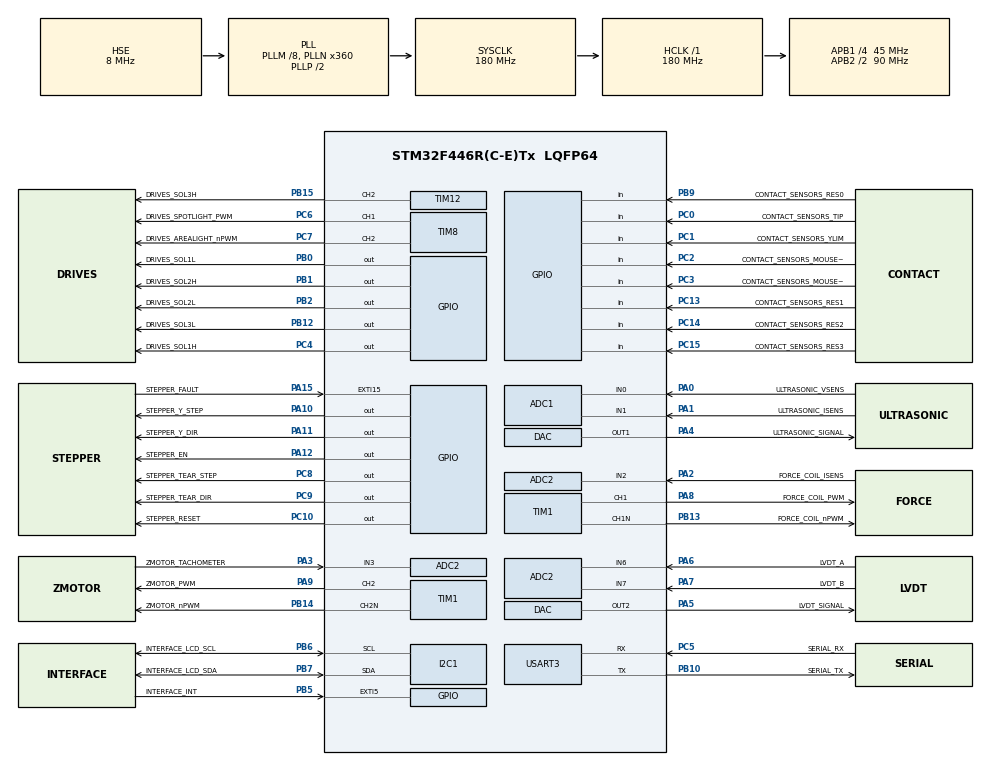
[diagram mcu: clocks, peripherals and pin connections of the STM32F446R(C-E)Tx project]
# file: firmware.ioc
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ADC1.Channel-1\#ChannelRegularConversion=ADC_CHANNEL_0
ADC1.Channel-2\#ChannelRegularConversion=ADC_CHANNEL_1
ADC1.ClockPrescaler=ADC_CLOCK_SYNC_PCLK_DIV4
ADC1.DMAContinuousRequests=ENABLE
ADC1.ExternalTrigConv=ADC_EXTERNALTRIGCONV_T2_TRGO
ADC1.NbrOfConversion=2
ADC1.NbrOfConversionFlag=1
ADC1.Rank-1\#ChannelRegularConversion=1
ADC1.Rank-2\#ChannelRegularConversion=2
ADC1.SamplingTime-1\#ChannelRegularConversion=ADC_SAMPLETIME_3CYCLES
ADC1.SamplingTime-2\#ChannelRegularConversion=ADC_SAMPLETIME_3CYCLES
ADC1.master=1
ADC2.Channel-0\#ChannelRegularConversion=ADC_CHANNEL_2
ADC2.Channel-1\#ChannelRegularConversion=ADC_CHANNEL_3
ADC2.Channel-2\#ChannelRegularConversion=ADC_CHANNEL_6
ADC2.Channel-3\#ChannelRegularConversion=ADC_CHANNEL_7
ADC2.DMAContinuousRequests=ENABLE
ADC2.ExternalTrigConv=ADC_EXTERNALTRIGCONV_T3_TRGO
ADC2.NbrOfConversion=4
ADC2.NbrOfConversionFlag=1
ADC2.Rank-0\#ChannelRegularConversion=1
ADC2.Rank-1\#ChannelRegularConversion=2
ADC2.Rank-2\#ChannelRegularConversion=3
ADC2.Rank-3\#ChannelRegularConversion=4
ADC2.SamplingTime-0\#ChannelRegularConversion=ADC_SAMPLETIME_15CYCLES
ADC2.SamplingTime-1\#ChannelRegularConversion=ADC_SAMPLETIME_15CYCLES
ADC2.SamplingTime-2\#ChannelRegularConversion=ADC_SAMPLETIME_15CYCLES
ADC2.SamplingTime-3\#ChannelRegularConversion=ADC_SAMPLETIME_15CYCLES
DAC.DAC_OutputBuffer=DAC_OUTPUTBUFFER_DISABLE
DAC.DAC_OutputBuffer2=DAC_OUTPUTBUFFER_DISABLE
DAC.DAC_Trigger=DAC_TRIGGER_T4_TRGO
DAC.DAC_Trigger2=DAC_TRIGGER_T5_TRGO
Dma.ADC1.2.Direction=DMA_PERIPH_TO_MEMORY
Dma.ADC1.2.FIFOMode=DMA_FIFOMODE_DISABLE
Dma.ADC1.2.Instance=DMA2_Stream0
Dma.ADC1.2.MemDataAlignment=DMA_MDATAALIGN_HALFWORD
Dma.ADC1.2.MemInc=DMA_MINC_ENABLE
Dma.ADC1.2.Mode=DMA_CIRCULAR
Dma.ADC1.2.PeriphDataAlignment=DMA_PDATAALIGN_HALFWORD
Dma.ADC1.2.PeriphInc=DMA_PINC_DISABLE
Dma.ADC1.2.Priority=DMA_PRIORITY_VERY_HIGH
Dma.ADC2.3.Direction=DMA_PERIPH_TO_MEMORY
Dma.ADC2.3.FIFOMode=DMA_FIFOMODE_DISABLE
Dma.ADC2.3.Instance=DMA2_Stream3
Dma.ADC2.3.MemDataAlignment=DMA_MDATAALIGN_HALFWORD
Dma.ADC2.3.MemInc=DMA_MINC_ENABLE
Dma.ADC2.3.Mode=DMA_CIRCULAR
Dma.ADC2.3.PeriphDataAlignment=DMA_PDATAALIGN_HALFWORD
Dma.ADC2.3.PeriphInc=DMA_PINC_DISABLE
Dma.ADC2.3.Priority=DMA_PRIORITY_HIGH
Dma.DAC1.0.Direction=DMA_MEMORY_TO_PERIPH
Dma.DAC1.0.FIFOMode=DMA_FIFOMODE_DISABLE
Dma.DAC1.0.Instance=DMA1_Stream5
Dma.DAC1.0.MemDataAlignment=DMA_MDATAALIGN_HALFWORD
Dma.DAC1.0.MemInc=DMA_MINC_ENABLE
Dma.DAC1.0.Mode=DMA_CIRCULAR
Dma.DAC1.0.PeriphDataAlignment=DMA_PDATAALIGN_HALFWORD
Dma.DAC1.0.PeriphInc=DMA_PINC_DISABLE
Dma.DAC1.0.Priority=DMA_PRIORITY_VERY_HIGH
Dma.DAC2.1.Direction=DMA_MEMORY_TO_PERIPH
Dma.DAC2.1.FIFOMode=DMA_FIFOMODE_DISABLE
Dma.DAC2.1.Instance=DMA1_Stream6
Dma.DAC2.1.MemDataAlignment=DMA_MDATAALIGN_HALFWORD
Dma.DAC2.1.MemInc=DMA_MINC_ENABLE
Dma.DAC2.1.Mode=DMA_CIRCULAR
Dma.DAC2.1.PeriphDataAlignment=DMA_PDATAALIGN_HALFWORD
Dma.DAC2.1.PeriphInc=DMA_PINC_DISABLE
Dma.DAC2.1.Priority=DMA_PRIORITY_HIGH
Dma.Request0=DAC1
Dma.Request1=DAC2
Dma.Request2=ADC1
Dma.Request3=ADC2
Dma.Request4=TIM1_CH1
Dma.Request5=TIM1_CH2
Dma.TIM1_CH1.4.Direction=DMA_MEMORY_TO_PERIPH
Dma.TIM1_CH1.4.FIFOMode=DMA_FIFOMODE_DISABLE
Dma.TIM1_CH1.4.Instance=DMA2_Stream1
Dma.TIM1_CH1.4.MemDataAlignment=DMA_MDATAALIGN_HALFWORD
Dma.TIM1_CH1.4.MemInc=DMA_MINC_ENABLE
Dma.TIM1_CH1.4.Mode=DMA_CIRCULAR
Dma.TIM1_CH1.4.PeriphDataAlignment=DMA_PDATAALIGN_HALFWORD
Dma.TIM1_CH1.4.PeriphInc=DMA_PINC_DISABLE
Dma.TIM1_CH1.4.Priority=DMA_PRIORITY_MEDIUM
Dma.TIM1_CH2.5.Direction=DMA_MEMORY_TO_PERIPH
Dma.TIM1_CH2.5.FIFOMode=DMA_FIFOMODE_DISABLE
Dma.TIM1_CH2.5.Instance=DMA2_Stream2
Dma.TIM1_CH2.5.MemDataAlignment=DMA_MDATAALIGN_HALFWORD
Dma.TIM1_CH2.5.MemInc=DMA_MINC_ENABLE
Dma.TIM1_CH2.5.Mode=DMA_CIRCULAR
Dma.TIM1_CH2.5.PeriphDataAlignment=DMA_PDATAALIGN_HALFWORD
Dma.TIM1_CH2.5.PeriphInc=DMA_PINC_DISABLE
Dma.TIM1_CH2.5.Priority=DMA_PRIORITY_MEDIUM
I2C1.I2C_Mode=I2C_Standard
Mcu.Family=STM32F4
Mcu.Name=STM32F446R(C-E)Tx
Mcu.Package=LQFP64
Mcu.UserConstants=TIM5_CLOCK_FREQ,90000000;ADC2_SAMPLING_FREQ,60000;DAC1_SAMPLING_FREQ,360000;ADC1_SAMPLING_FREQ,360000;DAC2_SAMPLING_FREQ,60000;STEPPER_ISR_FREQ,20000;TIM3_CLOCK_FREQ,90000000;TIM3_RELOAD_VALUE,((TIM3_CLOCK_FREQ/ADC2_SAMPLING_FREQ)-1);TIM1_CLOCK_FREQ,180000000;TIM4_RELOAD_VALUE,((TIM4_CLOCK_FREQ/DAC1_SAMPLING_FREQ)-1);TIM5_RELOAD_VALUE,((TIM5_CLOCK_FREQ/DAC2_SAMPLING_FREQ)-1);TIM6_RELOAD_VALUE,((TIM6_CLOCK_FREQ/STEPPER_ISR_FREQ)-1);TIM4_CLOCK_FREQ,90000000;TIM2_RELOAD_VALUE,((TIM2_CLOCK_FREQ/ADC1_SAMPLING_FREQ)-1);TIM6_CLOCK_FREQ,90000000;TIM1_PWM_FREQ,30000;TIM2_CLOCK_FREQ,90000000;TIM1_RELOAD_VALUE,((TIM1_CLOCK_FREQ/TIM1_PWM_FREQ)-1);TIM12_CLOCK_FREQ,90000000;TIM12_PWM_FREQ,20000;TIM12_RELOAD_VALUE,((TIM12_CLOCK_FREQ/TIM12_PWM_FREQ)-1)
NVIC.DMA1_Stream5_IRQn=true\:0\:0\:false\:false\:true\:false\:true\:true
NVIC.DMA1_Stream6_IRQn=true\:0\:0\:false\:false\:true\:false\:true\:true
NVIC.DMA2_Stream0_IRQn=true\:0\:0\:false\:false\:true\:false\:true\:true
NVIC.DMA2_Stream1_IRQn=true\:0\:0\:false\:false\:true\:false\:true\:true
NVIC.DMA2_Stream2_IRQn=true\:0\:0\:false\:false\:true\:false\:true\:true
NVIC.DMA2_Stream3_IRQn=true\:0\:0\:false\:false\:true\:false\:true\:true
NVIC.I2C1_EV_IRQn=true\:0\:0\:false\:false\:true\:true\:true\:true
NVIC.PriorityGroup=NVIC_PRIORITYGROUP_4
NVIC.TIM6_DAC_IRQn=true\:0\:0\:false\:false\:true\:true\:true\:true
PA0-WKUP.GPIO_Label=ULTRASONIC_VSENS
PA0-WKUP.Signal=ADCx_IN0
PA1.GPIO_Label=ULTRASONIC_ISENS
PA1.Signal=ADCx_IN1
PA10.GPIO_Label=STEPPER_Y_STEP
PA10.Signal=GPIO_Output
PA11.GPIO_Label=STEPPER_Y_DIR
PA11.Signal=GPIO_Output
PA12.GPIO_Label=STEPPER_EN
PA12.Signal=GPIO_Output
PA13.Mode=Serial_Wire
PA13.Signal=SYS_JTMS-SWDIO
PA14.Mode=Serial_Wire
PA14.Signal=SYS_JTCK-SWCLK
PA15.GPIO_Label=STEPPER_FAULT
PA15.Signal=GPXTI15
PA2.GPIO_Label=FORCE_COIL_ISENS
PA2.Signal=ADCx_IN2
PA3.GPIO_Label=ZMOTOR_TACHOMETER
PA3.Signal=ADCx_IN3
PA4.GPIO_Label=ULTRASONIC_SIGNAL
PA4.Signal=COMP_DAC1_group
PA5.GPIO_Label=LVDT_SIGNAL
PA5.Signal=COMP_DAC2_group
PA6.GPIO_Label=LVDT_A
PA6.Signal=ADCx_IN6
PA7.GPIO_Label=LVDT_B
PA7.Signal=ADCx_IN7
PA8.GPIO_Label=FORCE_COIL_PWM
PA8.Signal=S_TIM1_CH1
PA9.GPIO_Label=ZMOTOR_PWM
PA9.Signal=S_TIM1_CH2
PB0.GPIO_Label=DRIVES_SOL1L
PB0.PinState=GPIO_PIN_SET
PB0.Signal=GPIO_Output
PB1.GPIO_Label=DRIVES_SOL2H
PB1.Signal=GPIO_Output
PB10.GPIO_Label=SERIAL_TX
PB10.Mode=Asynchronous
PB10.Signal=USART3_TX
PB12.GPIO_Label=DRIVES_SOL3L
PB12.PinState=GPIO_PIN_SET
PB12.Signal=GPIO_Output
PB13.GPIO_Label=FORCE_COIL_nPWM
PB13.Mode=PWM Generation1 CH1 CH1N
PB13.Signal=TIM1_CH1N
PB14.GPIO_Label=ZMOTOR_nPWM
PB14.Mode=PWM Generation2 CH2 CH2N
PB14.Signal=TIM1_CH2N
PB15.GPIO_Label=DRIVES_SOL3H
PB15.Signal=S_TIM12_CH2
PB2.GPIO_Label=DRIVES_SOL2L
PB2.PinState=GPIO_PIN_SET
PB2.Signal=GPIO_Output
PB5.GPIO_Label=INTERFACE_INT
PB5.Signal=GPXTI5
PB6.GPIO_Label=INTERFACE_LCD_SCL
PB6.Mode=I2C
PB6.Signal=I2C1_SCL
PB7.GPIO_Label=INTERFACE_LCD_SDA
PB7.Mode=I2C
PB7.Signal=I2C1_SDA
PB9.GPIO_Label=CONTACT_SENSORS_RES0
PB9.Signal=GPIO_Input
PC0.GPIO_Label=CONTACT_SENSORS_TIP
PC0.Signal=GPIO_Input
PC1.GPIO_Label=CONTACT_SENSORS_YLIM
PC1.Signal=GPIO_Input
PC10.GPIO_Label=STEPPER_RESET
PC10.Signal=GPIO_Output
PC13.GPIO_Label=CONTACT_SENSORS_RES1
PC13.Signal=GPIO_Input
PC14-OSC32_IN.GPIO_Label=CONTACT_SENSORS_RES2
PC14-OSC32_IN.Signal=GPIO_Input
PC15-OSC32_OUT.GPIO_Label=CONTACT_SENSORS_RES3
PC15-OSC32_OUT.Signal=GPIO_Input
PC2.GPIO_Label=CONTACT_SENSORS_MOUSE_LEFT
PC2.Signal=GPIO_Input
PC3.GPIO_Label=CONTACT_SENSORS_MOUSE_RIGHT
PC3.Signal=GPIO_Input
PC4.GPIO_Label=DRIVES_SOL1H
PC4.Signal=GPIO_Output
PC5.GPIO_Label=SERIAL_RX
PC5.Mode=Asynchronous
PC5.Signal=USART3_RX
PC6.GPIO_Label=DRIVES_SPOTLIGHT_PWM
PC6.Signal=S_TIM8_CH1
PC7.GPIO_Label=DRIVES_AREALIGHT_nPWM
PC7.Signal=S_TIM8_CH2
PC8.GPIO_Label=STEPPER_TEAR_STEP
PC8.Signal=GPIO_Output
PC9.GPIO_Label=STEPPER_TEAR_DIR
PC9.Signal=GPIO_Output
PH0-OSC_IN.Mode=HSE-External-Oscillator
PH0-OSC_IN.Signal=RCC_OSC_IN
PH1-OSC_OUT.Mode=HSE-External-Oscillator
PH1-OSC_OUT.Signal=RCC_OSC_OUT
ProjectManager.HeapSize=0x200
ProjectManager.StackSize=0x400
ProjectManager.TargetToolchain=Makefile
RCC.AHBFreq_Value=180000000
RCC.APB1CLKDivider=RCC_HCLK_DIV4
RCC.APB1Freq_Value=45000000
RCC.APB1TimFreq_Value=90000000
RCC.APB2CLKDivider=RCC_HCLK_DIV2
RCC.APB2Freq_Value=90000000
RCC.APB2TimFreq_Value=180000000
RCC.CortexFreq_Value=180000000
RCC.HCLKFreq_Value=180000000
RCC.HSE_VALUE=8000000
RCC.PLLM=8
RCC.PLLN=360
RCC.PLLSourceVirtual=RCC_PLLSOURCE_HSE
RCC.SYSCLKFreq_VALUE=180000000
RCC.SYSCLKSource=RCC_SYSCLKSOURCE_PLLCLK
RCC.USBFreq_Value=180000000
RCC.VCOOutputFreq_Value=360000000
SH.ADCx_IN0.0=ADC1_IN0,IN0
SH.ADCx_IN1.0=ADC1_IN1,IN1
SH.ADCx_IN2.0=ADC2_IN2,IN2
SH.ADCx_IN3.0=ADC2_IN3,IN3
SH.ADCx_IN6.0=ADC2_IN6,IN6
SH.ADCx_IN7.0=ADC2_IN7,IN7
SH.COMP_DAC1_group.0=DAC_OUT1,DAC_OUT1
SH.COMP_DAC2_group.0=DAC_OUT2,DAC_OUT2
SH.S_TIM12_CH2.0=TIM12_CH2,PWM Generation2 CH2
SH.S_TIM1_CH1.0=TIM1_CH1,PWM Generation1 CH1 CH1N
SH.S_TIM1_CH2.0=TIM1_CH2,PWM Generation2 CH2 CH2N
SH.S_TIM8_CH1.0=TIM8_CH1,PWM Generation1 CH1
SH.S_TIM8_CH2.0=TIM8_CH2,PWM Generation2 CH2
TIM1.Channel-PWM\ Generation1\ CH1\ CH1N=TIM_CHANNEL_1
TIM1.Channel-PWM\ Generation2\ CH2\ CH2N=TIM_CHANNEL_2
TIM1.DeadTime=90
TIM1.Period=TIM1_RELOAD_VALUE
TIM12.Channel-PWM\ Generation2\ CH2=TIM_CHANNEL_2
TIM12.Period=TIM12_RELOAD_VALUE
TIM2.Period=TIM2_RELOAD_VALUE
TIM2.TIM_MasterOutputTrigger=TIM_TRGO_UPDATE
TIM3.Period=TIM3_RELOAD_VALUE
TIM3.TIM_MasterOutputTrigger=TIM_TRGO_UPDATE
TIM4.Period=TIM4_RELOAD_VALUE
TIM4.TIM_MasterOutputTrigger=TIM_TRGO_UPDATE
TIM5.Period=TIM5_RELOAD_VALUE
TIM5.TIM_MasterOutputTrigger=TIM_TRGO_UPDATE
TIM6.Period=TIM6_RELOAD_VALUE
TIM8.Channel-PWM\ Generation1\ CH1=TIM_CHANNEL_1
TIM8.Channel-PWM\ Generation2\ CH2=TIM_CHANNEL_2
USART3.VirtualMode=VM_ASYNC
VP_TIM12_VS_ClockSourceINT.Mode=Internal
VP_TIM1_VS_ClockSourceINT.Mode=Internal
VP_TIM2_VS_ClockSourceINT.Mode=Internal
VP_TIM3_VS_ClockSourceINT.Mode=Internal
VP_TIM4_VS_ClockSourceINT.Mode=Internal
VP_TIM5_VS_ClockSourceINT.Mode=Internal
VP_TIM6_VS_ClockSourceINT.Mode=Enable_Timer
VP_TIM8_VS_ClockSourceINT.Mode=Internal
board=custom

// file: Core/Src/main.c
/* USER CODE BEGIN Header */
/**
  ******************************************************************************
  * @file           : main.c
  * @brief          : Main program body
  ******************************************************************************
  * @attention
  *
  * Copyright (c) 2024 STMicroelectronics.
  * All rights reserved.
  *
  * This software is licensed under terms that can be found in the LICENSE file
  * in the root directory of this software component.
  * If no LICENSE file comes with this software, it is provided AS-IS.
  *
  ******************************************************************************
  */
/* USER CODE END Header */
#include "main.h"

/* USER CODE BEGIN Includes */
#include "app.h"
#include "configuration.h"
/* USER CODE END Includes */

ADC_HandleTypeDef hadc1;
ADC_HandleTypeDef hadc2;
DMA_HandleTypeDef hdma_adc1;
DMA_HandleTypeDef hdma_adc2;

DAC_HandleTypeDef hdac;
DMA_HandleTypeDef hdma_dac1;
DMA_HandleTypeDef hdma_dac2;

I2C_HandleTypeDef hi2c1;

TIM_HandleTypeDef htim1;
TIM_HandleTypeDef htim2;
TIM_HandleTypeDef htim3;
TIM_HandleTypeDef htim4;
TIM_HandleTypeDef htim5;
TIM_HandleTypeDef htim6;
TIM_HandleTypeDef htim8;
TIM_HandleTypeDef htim12;
DMA_HandleTypeDef hdma_tim1_ch1;
DMA_HandleTypeDef hdma_tim1_ch2;

UART_HandleTypeDef huart3;

void SystemClock_Config(void);
static void MX_GPIO_Init(void);
static void MX_DMA_Init(void);
static void MX_DAC_Init(void);
static void MX_ADC1_Init(void);
static void MX_ADC2_Init(void);
static void MX_I2C1_Init(void);
static void MX_TIM1_Init(void);
static void MX_TIM3_Init(void);
static void MX_TIM8_Init(void);
static void MX_USART3_UART_Init(void);
static void MX_TIM2_Init(void);
static void MX_TIM4_Init(void);
static void MX_TIM5_Init(void);
static void MX_TIM6_Init(void);
static void MX_TIM12_Init(void);

int main(void)
{

  /* MCU Configuration--------------------------------------------------------*/

  /* Reset of all peripherals, Initializes the Flash interface and the Systick. */
  HAL_Init();

  /* Configure the system clock */
  SystemClock_Config();

  /* Initialize all configured peripherals */
  MX_GPIO_Init();
  MX_DMA_Init();
  MX_DAC_Init();
  MX_ADC1_Init();
  MX_ADC2_Init();
  MX_I2C1_Init();
  MX_TIM1_Init();
  MX_TIM3_Init();
  MX_TIM8_Init();
  MX_USART3_UART_Init();
  MX_TIM2_Init();
  MX_TIM4_Init();
  MX_TIM5_Init();
  MX_TIM6_Init();
  MX_TIM12_Init();
  /* USER CODE BEGIN 2 */
  App_Init();
  App_Start();
  /* USER CODE END 2 */

  /* Infinite loop */
  while (1)
  {

    /* USER CODE BEGIN 3 */
    App_Execute();
  }
  /* USER CODE END 3 */
}

void SystemClock_Config(void)
{
  RCC_OscInitTypeDef RCC_OscInitStruct = {0};
  RCC_ClkInitTypeDef RCC_ClkInitStruct = {0};

  /** Configure the main internal regulator output voltage
  */
  __HAL_RCC_PWR_CLK_ENABLE();
  __HAL_PWR_VOLTAGESCALING_CONFIG(PWR_REGULATOR_VOLTAGE_SCALE1);

  /** Initializes the RCC Oscillators according to the specified parameters
  * in the RCC_OscInitTypeDef structure.
  */
  RCC_OscInitStruct.OscillatorType = RCC_OSCILLATORTYPE_HSE;
  RCC_OscInitStruct.HSEState = RCC_HSE_ON;
  RCC_OscInitStruct.PLL.PLLState = RCC_PLL_ON;
  RCC_OscInitStruct.PLL.PLLSource = RCC_PLLSOURCE_HSE;
  RCC_OscInitStruct.PLL.PLLM = 8;
  RCC_OscInitStruct.PLL.PLLN = 360;
  RCC_OscInitStruct.PLL.PLLP = RCC_PLLP_DIV2;
  RCC_OscInitStruct.PLL.PLLQ = 2;
  RCC_OscInitStruct.PLL.PLLR = 2;
  if (HAL_RCC_OscConfig(&RCC_OscInitStruct) != HAL_OK)
  {
    Error_Handler();
  }

  /** Activate the Over-Drive mode
  */
  if (HAL_PWREx_EnableOverDrive() != HAL_OK)
  {
    Error_Handler();
  }

  /** Initializes the CPU, AHB and APB buses clocks
  */
  RCC_ClkInitStruct.ClockType = RCC_CLOCKTYPE_HCLK|RCC_CLOCKTYPE_SYSCLK
                              |RCC_CLOCKTYPE_PCLK1|RCC_CLOCKTYPE_PCLK2;
  RCC_ClkInitStruct.SYSCLKSource = RCC_SYSCLKSOURCE_PLLCLK;
  RCC_ClkInitStruct.AHBCLKDivider = RCC_SYSCLK_DIV1;
  RCC_ClkInitStruct.APB1CLKDivider = RCC_HCLK_DIV4;
  RCC_ClkInitStruct.APB2CLKDivider = RCC_HCLK_DIV2;

  if (HAL_RCC_ClockConfig(&RCC_ClkInitStruct, FLASH_LATENCY_5) != HAL_OK)
  {
    Error_Handler();
  }
}

static void MX_ADC1_Init(void)
{

  ADC_ChannelConfTypeDef sConfig = {0};

  /** Configure the global features of the ADC (Clock, Resolution, Data Alignment and number of conversion)
  */
  hadc1.Instance = ADC1;
  hadc1.Init.ClockPrescaler = ADC_CLOCK_SYNC_PCLK_DIV4;
  hadc1.Init.Resolution = ADC_RESOLUTION_12B;
  hadc1.Init.ScanConvMode = ENABLE;
  hadc1.Init.ContinuousConvMode = DISABLE;
  hadc1.Init.DiscontinuousConvMode = DISABLE;
  hadc1.Init.ExternalTrigConvEdge = ADC_EXTERNALTRIGCONVEDGE_RISING;
  hadc1.Init.ExternalTrigConv = ADC_EXTERNALTRIGCONV_T2_TRGO;
  hadc1.Init.DataAlign = ADC_DATAALIGN_RIGHT;
  hadc1.Init.NbrOfConversion = 2;
  hadc1.Init.DMAContinuousRequests = ENABLE;
  hadc1.Init.EOCSelection = ADC_EOC_SINGLE_CONV;
  if (HAL_ADC_Init(&hadc1) != HAL_OK)
  {
    Error_Handler();
  }

  /** Configure for the selected ADC regular channel its corresponding rank in the sequencer and its sample time.
  */
  sConfig.Channel = ADC_CHANNEL_0;
  sConfig.Rank = 1;
  sConfig.SamplingTime = ADC_SAMPLETIME_3CYCLES;
  if (HAL_ADC_ConfigChannel(&hadc1, &sConfig) != HAL_OK)
  {
    Error_Handler();
  }

  /** Configure for the selected ADC regular channel its corresponding rank in the sequencer and its sample time.
  */
  sConfig.Channel = ADC_CHANNEL_1;
  sConfig.Rank = 2;
  if (HAL_ADC_ConfigChannel(&hadc1, &sConfig) != HAL_OK)
  {
    Error_Handler();
  }

}

static void MX_ADC2_Init(void)
{

  ADC_ChannelConfTypeDef sConfig = {0};

  /** Configure the global features of the ADC (Clock, Resolution, Data Alignment and number of conversion)
  */
  hadc2.Instance = ADC2;
  hadc2.Init.ClockPrescaler = ADC_CLOCK_SYNC_PCLK_DIV4;
  hadc2.Init.Resolution = ADC_RESOLUTION_12B;
  hadc2.Init.ScanConvMode = ENABLE;
  hadc2.Init.ContinuousConvMode = DISABLE;
  hadc2.Init.DiscontinuousConvMode = DISABLE;
  hadc2.Init.ExternalTrigConvEdge = ADC_EXTERNALTRIGCONVEDGE_RISING;
  hadc2.Init.ExternalTrigConv = ADC_EXTERNALTRIGCONV_T3_TRGO;
  hadc2.Init.DataAlign = ADC_DATAALIGN_RIGHT;
  hadc2.Init.NbrOfConversion = 4;
  hadc2.Init.DMAContinuousRequests = ENABLE;
  hadc2.Init.EOCSelection = ADC_EOC_SINGLE_CONV;
  if (HAL_ADC_Init(&hadc2) != HAL_OK)
  {
    Error_Handler();
  }

  /** Configure for the selected ADC regular channel its corresponding rank in the sequencer and its sample time.
  */
  sConfig.Channel = ADC_CHANNEL_2;
  sConfig.Rank = 1;
  sConfig.SamplingTime = ADC_SAMPLETIME_15CYCLES;
  if (HAL_ADC_ConfigChannel(&hadc2, &sConfig) != HAL_OK)
  {
    Error_Handler();
  }

  /** Configure for the selected ADC regular channel its corresponding rank in the sequencer and its sample time.
  */
  sConfig.Channel = ADC_CHANNEL_3;
  sConfig.Rank = 2;
  if (HAL_ADC_ConfigChannel(&hadc2, &sConfig) != HAL_OK)
  {
    Error_Handler();
  }

  /** Configure for the selected ADC regular channel its corresponding rank in the sequencer and its sample time.
  */
  sConfig.Channel = ADC_CHANNEL_6;
  sConfig.Rank = 3;
  if (HAL_ADC_ConfigChannel(&hadc2, &sConfig) != HAL_OK)
  {
    Error_Handler();
  }

  /** Configure for the selected ADC regular channel its corresponding rank in the sequencer and its sample time.
  */
  sConfig.Channel = ADC_CHANNEL_7;
  sConfig.Rank = 4;
  if (HAL_ADC_ConfigChannel(&hadc2, &sConfig) != HAL_OK)
  {
    Error_Handler();
  }

}

static void MX_DAC_Init(void)
{

  DAC_ChannelConfTypeDef sConfig = {0};

  /** DAC Initialization
  */
  hdac.Instance = DAC;
  if (HAL_DAC_Init(&hdac) != HAL_OK)
  {
    Error_Handler();
  }

  /** DAC channel OUT1 config
  */
  sConfig.DAC_Trigger = DAC_TRIGGER_T4_TRGO;
  sConfig.DAC_OutputBuffer = DAC_OUTPUTBUFFER_DISABLE;
  if (HAL_DAC_ConfigChannel(&hdac, &sConfig, DAC_CHANNEL_1) != HAL_OK)
  {
    Error_Handler();
  }

  /** DAC channel OUT2 config
  */
  sConfig.DAC_Trigger = DAC_TRIGGER_T5_TRGO;
  if (HAL_DAC_ConfigChannel(&hdac, &sConfig, DAC_CHANNEL_2) != HAL_OK)
  {
    Error_Handler();
  }

}

static void MX_I2C1_Init(void)
{

  hi2c1.Instance = I2C1;
  hi2c1.Init.ClockSpeed = 100000;
  hi2c1.Init.DutyCycle = I2C_DUTYCYCLE_2;
  hi2c1.Init.OwnAddress1 = 0;
  hi2c1.Init.AddressingMode = I2C_ADDRESSINGMODE_7BIT;
  hi2c1.Init.DualAddressMode = I2C_DUALADDRESS_DISABLE;
  hi2c1.Init.OwnAddress2 = 0;
  hi2c1.Init.GeneralCallMode = I2C_GENERALCALL_DISABLE;
  hi2c1.Init.NoStretchMode = I2C_NOSTRETCH_DISABLE;
  if (HAL_I2C_Init(&hi2c1) != HAL_OK)
  {
    Error_Handler();
  }

}

static void MX_TIM1_Init(void)
{

  TIM_ClockConfigTypeDef sClockSourceConfig = {0};
  TIM_MasterConfigTypeDef sMasterConfig = {0};
  TIM_OC_InitTypeDef sConfigOC = {0};
  TIM_BreakDeadTimeConfigTypeDef sBreakDeadTimeConfig = {0};

  htim1.Instance = TIM1;
  htim1.Init.Prescaler = 0;
  htim1.Init.CounterMode = TIM_COUNTERMODE_UP;
  htim1.Init.Period = TIM1_RELOAD_VALUE;
  htim1.Init.ClockDivision = TIM_CLOCKDIVISION_DIV1;
  htim1.Init.RepetitionCounter = 0;
  htim1.Init.AutoReloadPreload = TIM_AUTORELOAD_PRELOAD_DISABLE;
  if (HAL_TIM_Base_Init(&htim1) != HAL_OK)
  {
    Error_Handler();
  }
  sClockSourceConfig.ClockSource = TIM_CLOCKSOURCE_INTERNAL;
  if (HAL_TIM_ConfigClockSource(&htim1, &sClockSourceConfig) != HAL_OK)
  {
    Error_Handler();
  }
  if (HAL_TIM_PWM_Init(&htim1) != HAL_OK)
  {
    Error_Handler();
  }
  sMasterConfig.MasterOutputTrigger = TIM_TRGO_RESET;
  sMasterConfig.MasterSlaveMode = TIM_MASTERSLAVEMODE_DISABLE;
  if (HAL_TIMEx_MasterConfigSynchronization(&htim1, &sMasterConfig) != HAL_OK)
  {
    Error_Handler();
  }
  sConfigOC.OCMode = TIM_OCMODE_PWM1;
  sConfigOC.Pulse = 0;
  sConfigOC.OCPolarity = TIM_OCPOLARITY_HIGH;
  sConfigOC.OCNPolarity = TIM_OCNPOLARITY_HIGH;
  sConfigOC.OCFastMode = TIM_OCFAST_DISABLE;
  sConfigOC.OCIdleState = TIM_OCIDLESTATE_RESET;
  sConfigOC.OCNIdleState = TIM_OCNIDLESTATE_RESET;
  if (HAL_TIM_PWM_ConfigChannel(&htim1, &sConfigOC, TIM_CHANNEL_1) != HAL_OK)
  {
    Error_Handler();
  }
  if (HAL_TIM_PWM_ConfigChannel(&htim1, &sConfigOC, TIM_CHANNEL_2) != HAL_OK)
  {
    Error_Handler();
  }
  sBreakDeadTimeConfig.OffStateRunMode = TIM_OSSR_DISABLE;
  sBreakDeadTimeConfig.OffStateIDLEMode = TIM_OSSI_DISABLE;
  sBreakDeadTimeConfig.LockLevel = TIM_LOCKLEVEL_OFF;
  sBreakDeadTimeConfig.DeadTime = 90;
  sBreakDeadTimeConfig.BreakState = TIM_BREAK_DISABLE;
  sBreakDeadTimeConfig.BreakPolarity = TIM_BREAKPOLARITY_HIGH;
  sBreakDeadTimeConfig.AutomaticOutput = TIM_AUTOMATICOUTPUT_DISABLE;
  if (HAL_TIMEx_ConfigBreakDeadTime(&htim1, &sBreakDeadTimeConfig) != HAL_OK)
  {
    Error_Handler();
  }
  HAL_TIM_MspPostInit(&htim1);

}

static void MX_TIM2_Init(void)
{

  TIM_ClockConfigTypeDef sClockSourceConfig = {0};
  TIM_MasterConfigTypeDef sMasterConfig = {0};

  htim2.Instance = TIM2;
  htim2.Init.Prescaler = 0;
  htim2.Init.CounterMode = TIM_COUNTERMODE_UP;
  htim2.Init.Period = TIM2_RELOAD_VALUE;
  htim2.Init.ClockDivision = TIM_CLOCKDIVISION_DIV1;
  htim2.Init.AutoReloadPreload = TIM_AUTORELOAD_PRELOAD_DISABLE;
  if (HAL_TIM_Base_Init(&htim2) != HAL_OK)
  {
    Error_Handler();
  }
  sClockSourceConfig.ClockSource = TIM_CLOCKSOURCE_INTERNAL;
  if (HAL_TIM_ConfigClockSource(&htim2, &sClockSourceConfig) != HAL_OK)
  {
    Error_Handler();
  }
  sMasterConfig.MasterOutputTrigger = TIM_TRGO_UPDATE;
  sMasterConfig.MasterSlaveMode = TIM_MASTERSLAVEMODE_DISABLE;
  if (HAL_TIMEx_MasterConfigSynchronization(&htim2, &sMasterConfig) != HAL_OK)
  {
    Error_Handler();
  }

}

static void MX_TIM3_Init(void)
{

  TIM_ClockConfigTypeDef sClockSourceConfig = {0};
  TIM_MasterConfigTypeDef sMasterConfig = {0};

  htim3.Instance = TIM3;
  htim3.Init.Prescaler = 0;
  htim3.Init.CounterMode = TIM_COUNTERMODE_UP;
  htim3.Init.Period = TIM3_RELOAD_VALUE;
  htim3.Init.ClockDivision = TIM_CLOCKDIVISION_DIV1;
  htim3.Init.AutoReloadPreload = TIM_AUTORELOAD_PRELOAD_DISABLE;
  if (HAL_TIM_Base_Init(&htim3) != HAL_OK)
  {
    Error_Handler();
  }
  sClockSourceConfig.ClockSource = TIM_CLOCKSOURCE_INTERNAL;
  if (HAL_TIM_ConfigClockSource(&htim3, &sClockSourceConfig) != HAL_OK)
  {
    Error_Handler();
  }
  sMasterConfig.MasterOutputTrigger = TIM_TRGO_UPDATE;
  sMasterConfig.MasterSlaveMode = TIM_MASTERSLAVEMODE_DISABLE;
  if (HAL_TIMEx_MasterConfigSynchronization(&htim3, &sMasterConfig) != HAL_OK)
  {
    Error_Handler();
  }

}

static void MX_TIM4_Init(void)
{

  TIM_ClockConfigTypeDef sClockSourceConfig = {0};
  TIM_MasterConfigTypeDef sMasterConfig = {0};

  htim4.Instance = TIM4;
  htim4.Init.Prescaler = 0;
  htim4.Init.CounterMode = TIM_COUNTERMODE_UP;
  htim4.Init.Period = TIM4_RELOAD_VALUE;
  htim4.Init.ClockDivision = TIM_CLOCKDIVISION_DIV1;
  htim4.Init.AutoReloadPreload = TIM_AUTORELOAD_PRELOAD_DISABLE;
  if (HAL_TIM_Base_Init(&htim4) != HAL_OK)
  {
    Error_Handler();
  }
  sClockSourceConfig.ClockSource = TIM_CLOCKSOURCE_INTERNAL;
  if (HAL_TIM_ConfigClockSource(&htim4, &sClockSourceConfig) != HAL_OK)
  {
    Error_Handler();
  }
  sMasterConfig.MasterOutputTrigger = TIM_TRGO_UPDATE;
  sMasterConfig.MasterSlaveMode = TIM_MASTERSLAVEMODE_DISABLE;
  if (HAL_TIMEx_MasterConfigSynchronization(&htim4, &sMasterConfig) != HAL_OK)
  {
    Error_Handler();
  }

}

static void MX_TIM5_Init(void)
{

  TIM_ClockConfigTypeDef sClockSourceConfig = {0};
  TIM_MasterConfigTypeDef sMasterConfig = {0};

  htim5.Instance = TIM5;
  htim5.Init.Prescaler = 0;
  htim5.Init.CounterMode = TIM_COUNTERMODE_UP;
  htim5.Init.Period = TIM5_RELOAD_VALUE;
  htim5.Init.ClockDivision = TIM_CLOCKDIVISION_DIV1;
  htim5.Init.AutoReloadPreload = TIM_AUTORELOAD_PRELOAD_DISABLE;
  if (HAL_TIM_Base_Init(&htim5) != HAL_OK)
  {
    Error_Handler();
  }
  sClockSourceConfig.ClockSource = TIM_CLOCKSOURCE_INTERNAL;
  if (HAL_TIM_ConfigClockSource(&htim5, &sClockSourceConfig) != HAL_OK)
  {
    Error_Handler();
  }
  sMasterConfig.MasterOutputTrigger = TIM_TRGO_UPDATE;
  sMasterConfig.MasterSlaveMode = TIM_MASTERSLAVEMODE_DISABLE;
  if (HAL_TIMEx_MasterConfigSynchronization(&htim5, &sMasterConfig) != HAL_OK)
  {
    Error_Handler();
  }

}

static void MX_TIM6_Init(void)
{

  TIM_MasterConfigTypeDef sMasterConfig = {0};

  htim6.Instance = TIM6;
  htim6.Init.Prescaler = 0;
  htim6.Init.CounterMode = TIM_COUNTERMODE_UP;
  htim6.Init.Period = TIM6_RELOAD_VALUE;
  htim6.Init.AutoReloadPreload = TIM_AUTORELOAD_PRELOAD_DISABLE;
  if (HAL_TIM_Base_Init(&htim6) != HAL_OK)
  {
    Error_Handler();
  }
  sMasterConfig.MasterOutputTrigger = TIM_TRGO_RESET;
  sMasterConfig.MasterSlaveMode = TIM_MASTERSLAVEMODE_DISABLE;
  if (HAL_TIMEx_MasterConfigSynchronization(&htim6, &sMasterConfig) != HAL_OK)
  {
    Error_Handler();
  }

}

static void MX_TIM8_Init(void)
{

  TIM_ClockConfigTypeDef sClockSourceConfig = {0};
  TIM_MasterConfigTypeDef sMasterConfig = {0};
  TIM_OC_InitTypeDef sConfigOC = {0};
  TIM_BreakDeadTimeConfigTypeDef sBreakDeadTimeConfig = {0};

  htim8.Instance = TIM8;
  htim8.Init.Prescaler = 0;
  htim8.Init.CounterMode = TIM_COUNTERMODE_UP;
  htim8.Init.Period = 65535;
  htim8.Init.ClockDivision = TIM_CLOCKDIVISION_DIV1;
  htim8.Init.RepetitionCounter = 0;
  htim8.Init.AutoReloadPreload = TIM_AUTORELOAD_PRELOAD_DISABLE;
  if (HAL_TIM_Base_Init(&htim8) != HAL_OK)
  {
    Error_Handler();
  }
  sClockSourceConfig.ClockSource = TIM_CLOCKSOURCE_INTERNAL;
  if (HAL_TIM_ConfigClockSource(&htim8, &sClockSourceConfig) != HAL_OK)
  {
    Error_Handler();
  }
  if (HAL_TIM_PWM_Init(&htim8) != HAL_OK)
  {
    Error_Handler();
  }
  sMasterConfig.MasterOutputTrigger = TIM_TRGO_RESET;
  sMasterConfig.MasterSlaveMode = TIM_MASTERSLAVEMODE_DISABLE;
  if (HAL_TIMEx_MasterConfigSynchronization(&htim8, &sMasterConfig) != HAL_OK)
  {
    Error_Handler();
  }
  sConfigOC.OCMode = TIM_OCMODE_PWM1;
  sConfigOC.Pulse = 0;
  sConfigOC.OCPolarity = TIM_OCPOLARITY_HIGH;
  sConfigOC.OCNPolarity = TIM_OCNPOLARITY_HIGH;
  sConfigOC.OCFastMode = TIM_OCFAST_DISABLE;
  sConfigOC.OCIdleState = TIM_OCIDLESTATE_RESET;
  sConfigOC.OCNIdleState = TIM_OCNIDLESTATE_RESET;
  if (HAL_TIM_PWM_ConfigChannel(&htim8, &sConfigOC, TIM_CHANNEL_1) != HAL_OK)
  {
    Error_Handler();
  }
  if (HAL_TIM_PWM_ConfigChannel(&htim8, &sConfigOC, TIM_CHANNEL_2) != HAL_OK)
  {
    Error_Handler();
  }
  sBreakDeadTimeConfig.OffStateRunMode = TIM_OSSR_DISABLE;
  sBreakDeadTimeConfig.OffStateIDLEMode = TIM_OSSI_DISABLE;
  sBreakDeadTimeConfig.LockLevel = TIM_LOCKLEVEL_OFF;
  sBreakDeadTimeConfig.DeadTime = 0;
  sBreakDeadTimeConfig.BreakState = TIM_BREAK_DISABLE;
  sBreakDeadTimeConfig.BreakPolarity = TIM_BREAKPOLARITY_HIGH;
  sBreakDeadTimeConfig.AutomaticOutput = TIM_AUTOMATICOUTPUT_DISABLE;
  if (HAL_TIMEx_ConfigBreakDeadTime(&htim8, &sBreakDeadTimeConfig) != HAL_OK)
  {
    Error_Handler();
  }
  /* USER CODE BEGIN TIM8_Init 2 */

  /* The area light driver is active low (DRIVES_AREALIGHT_nPWM): the lamp is
     lit while PC7 is low. Drive both channels *before* HAL_TIM_MspPostInit()
     hands the pins to the timer, otherwise PC7 sits at its uncontrolled
     default (low, i.e. the lamp at full supply voltage) from the moment it
     becomes an alternate function until Robot::start() gets to it.

     Robot::start() brings the area light up energized, but it cannot do so
     until UserInterfaceModule::onStart() has loaded the stored brightness --
     roughly 150 ms in, behind SolenoidService's blocking init delay. Parking
     the channel off here would therefore blink the lamp off and back on
     during start-up, so park it at the default level instead: the lamp stays
     continuously lit from reset, and Robot::start() only has to correct the
     brightness if the operator has stored something other than the default. */
  __HAL_TIM_SET_COMPARE(&htim8, TIM_CHANNEL_1, 0);                     /* spotlight off (active high) */
  __HAL_TIM_SET_COMPARE(&htim8, TIM_CHANNEL_2,
      (uint32_t)((1.0f - (AREA_LIGHT_LEVEL_DEFAULT / 100.0f) *
                         (AREA_LIGHT_MAX_VOLTAGE / AREA_LIGHT_SUPPLY_VOLTAGE)) *
                 (float)htim8.Init.Period));
  if (HAL_TIM_PWM_Start(&htim8, TIM_CHANNEL_1) != HAL_OK)
  {
    Error_Handler();
  }
  if (HAL_TIM_PWM_Start(&htim8, TIM_CHANNEL_2) != HAL_OK)
  {
    Error_Handler();
  }

  /* USER CODE END TIM8_Init 2 */
  HAL_TIM_MspPostInit(&htim8);

}

static void MX_TIM12_Init(void)
{

  TIM_ClockConfigTypeDef sClockSourceConfig = {0};
  TIM_OC_InitTypeDef sConfigOC = {0};

  htim12.Instance = TIM12;
  htim12.Init.Prescaler = 0;
  htim12.Init.CounterMode = TIM_COUNTERMODE_UP;
  htim12.Init.Period = TIM12_RELOAD_VALUE;
  htim12.Init.ClockDivision = TIM_CLOCKDIVISION_DIV1;
  htim12.Init.AutoReloadPreload = TIM_AUTORELOAD_PRELOAD_DISABLE;
  if (HAL_TIM_Base_Init(&htim12) != HAL_OK)
  {
    Error_Handler();
  }
  sClockSourceConfig.ClockSource = TIM_CLOCKSOURCE_INTERNAL;
  if (HAL_TIM_ConfigClockSource(&htim12, &sClockSourceConfig) != HAL_OK)
  {
    Error_Handler();
  }
  if (HAL_TIM_PWM_Init(&htim12) != HAL_OK)
  {
    Error_Handler();
  }
  sConfigOC.OCMode = TIM_OCMODE_PWM1;
  sConfigOC.Pulse = 0;
  sConfigOC.OCPolarity = TIM_OCPOLARITY_HIGH;
  sConfigOC.OCFastMode = TIM_OCFAST_DISABLE;
  if (HAL_TIM_PWM_ConfigChannel(&htim12, &sConfigOC, TIM_CHANNEL_2) != HAL_OK)
  {
    Error_Handler();
  }
  HAL_TIM_MspPostInit(&htim12);

}

static void MX_USART3_UART_Init(void)
{

  huart3.Instance = USART3;
  huart3.Init.BaudRate = 115200;
  huart3.Init.WordLength = UART_WORDLENGTH_8B;
  huart3.Init.StopBits = UART_STOPBITS_1;
  huart3.Init.Parity = UART_PARITY_NONE;
  huart3.Init.Mode = UART_MODE_TX_RX;
  huart3.Init.HwFlowCtl = UART_HWCONTROL_NONE;
  huart3.Init.OverSampling = UART_OVERSAMPLING_16;
  if (HAL_UART_Init(&huart3) != HAL_OK)
  {
    Error_Handler();
  }

}

static void MX_DMA_Init(void)
{

  /* DMA controller clock enable */
  __HAL_RCC_DMA1_CLK_ENABLE();
  __HAL_RCC_DMA2_CLK_ENABLE();

  /* DMA interrupt init */
  /* DMA1_Stream5_IRQn interrupt configuration */
  HAL_NVIC_SetPriority(DMA1_Stream5_IRQn, 0, 0);
  HAL_NVIC_EnableIRQ(DMA1_Stream5_IRQn);
  /* DMA1_Stream6_IRQn interrupt configuration */
  HAL_NVIC_SetPriority(DMA1_Stream6_IRQn, 0, 0);
  HAL_NVIC_EnableIRQ(DMA1_Stream6_IRQn);
  /* DMA2_Stream0_IRQn interrupt configuration */
  HAL_NVIC_SetPriority(DMA2_Stream0_IRQn, 0, 0);
  HAL_NVIC_EnableIRQ(DMA2_Stream0_IRQn);
  /* DMA2_Stream1_IRQn interrupt configuration */
  HAL_NVIC_SetPriority(DMA2_Stream1_IRQn, 0, 0);
  HAL_NVIC_EnableIRQ(DMA2_Stream1_IRQn);
  /* DMA2_Stream2_IRQn interrupt configuration */
  HAL_NVIC_SetPriority(DMA2_Stream2_IRQn, 0, 0);
  HAL_NVIC_EnableIRQ(DMA2_Stream2_IRQn);
  /* DMA2_Stream3_IRQn interrupt configuration */
  HAL_NVIC_SetPriority(DMA2_Stream3_IRQn, 0, 0);
  HAL_NVIC_EnableIRQ(DMA2_Stream3_IRQn);

}

static void MX_GPIO_Init(void)
{
  GPIO_InitTypeDef GPIO_InitStruct = {0};

  /* GPIO Ports Clock Enable */
  __HAL_RCC_GPIOC_CLK_ENABLE();
  __HAL_RCC_GPIOH_CLK_ENABLE();
  __HAL_RCC_GPIOA_CLK_ENABLE();
  __HAL_RCC_GPIOB_CLK_ENABLE();

  /*Configure GPIO pin Output Level */
  HAL_GPIO_WritePin(GPIOC, DRIVES_SOL1H_Pin|STEPPER_TEAR_STEP_Pin|STEPPER_TEAR_DIR_Pin|STEPPER_RESET_Pin, GPIO_PIN_RESET);

  /*Configure GPIO pin Output Level */
  HAL_GPIO_WritePin(GPIOB, DRIVES_SOL1L_Pin|DRIVES_SOL2L_Pin|DRIVES_SOL3L_Pin, GPIO_PIN_SET);

  /*Configure GPIO pin Output Level */
  HAL_GPIO_WritePin(DRIVES_SOL2H_GPIO_Port, DRIVES_SOL2H_Pin, GPIO_PIN_RESET);

  /*Configure GPIO pin Output Level */
  HAL_GPIO_WritePin(GPIOA, STEPPER_Y_STEP_Pin|STEPPER_Y_DIR_Pin|STEPPER_EN_Pin, GPIO_PIN_RESET);

  /*Configure GPIO pins : CONTACT_SENSORS_RES1_Pin CONTACT_SENSORS_RES2_Pin CONTACT_SENSORS_RES3_Pin CONTACT_SENSORS_TIP_Pin
                           CONTACT_SENSORS_YLIM_Pin CONTACT_SENSORS_MOUSE_LEFT_Pin CONTACT_SENSORS_MOUSE_RIGHT_Pin */
  GPIO_InitStruct.Pin = CONTACT_SENSORS_RES1_Pin|CONTACT_SENSORS_RES2_Pin|CONTACT_SENSORS_RES3_Pin|CONTACT_SENSORS_TIP_Pin
                          |CONTACT_SENSORS_YLIM_Pin|CONTACT_SENSORS_MOUSE_LEFT_Pin|CONTACT_SENSORS_MOUSE_RIGHT_Pin;
  GPIO_InitStruct.Mode = GPIO_MODE_INPUT;
  GPIO_InitStruct.Pull = GPIO_NOPULL;
  HAL_GPIO_Init(GPIOC, &GPIO_InitStruct);

  /*Configure GPIO pins : DRIVES_SOL1H_Pin STEPPER_TEAR_STEP_Pin STEPPER_TEAR_DIR_Pin STEPPER_RESET_Pin */
  GPIO_InitStruct.Pin = DRIVES_SOL1H_Pin|STEPPER_TEAR_STEP_Pin|STEPPER_TEAR_DIR_Pin|STEPPER_RESET_Pin;
  GPIO_InitStruct.Mode = GPIO_MODE_OUTPUT_PP;
  GPIO_InitStruct.Pull = GPIO_NOPULL;
  GPIO_InitStruct.Speed = GPIO_SPEED_FREQ_LOW;
  HAL_GPIO_Init(GPIOC, &GPIO_InitStruct);

  /*Configure GPIO pins : DRIVES_SOL1L_Pin DRIVES_SOL2H_Pin DRIVES_SOL2L_Pin DRIVES_SOL3L_Pin */
  GPIO_InitStruct.Pin = DRIVES_SOL1L_Pin|DRIVES_SOL2H_Pin|DRIVES_SOL2L_Pin|DRIVES_SOL3L_Pin;
  GPIO_InitStruct.Mode = GPIO_MODE_OUTPUT_PP;
  GPIO_InitStruct.Pull = GPIO_NOPULL;
  GPIO_InitStruct.Speed = GPIO_SPEED_FREQ_LOW;
  HAL_GPIO_Init(GPIOB, &GPIO_InitStruct);

  /*Configure GPIO pins : STEPPER_Y_STEP_Pin STEPPER_Y_DIR_Pin STEPPER_EN_Pin */
  GPIO_InitStruct.Pin = STEPPER_Y_STEP_Pin|STEPPER_Y_DIR_Pin|STEPPER_EN_Pin;
  GPIO_InitStruct.Mode = GPIO_MODE_OUTPUT_PP;
  GPIO_InitStruct.Pull = GPIO_NOPULL;
  GPIO_InitStruct.Speed = GPIO_SPEED_FREQ_LOW;
  HAL_GPIO_Init(GPIOA, &GPIO_InitStruct);

  /*Configure GPIO pin : STEPPER_FAULT_Pin */
  GPIO_InitStruct.Pin = STEPPER_FAULT_Pin;
  GPIO_InitStruct.Mode = GPIO_MODE_IT_RISING;
  GPIO_InitStruct.Pull = GPIO_NOPULL;
  HAL_GPIO_Init(STEPPER_FAULT_GPIO_Port, &GPIO_InitStruct);

  /*Configure GPIO pin : INTERFACE_INT_Pin */
  GPIO_InitStruct.Pin = INTERFACE_INT_Pin;
  GPIO_InitStruct.Mode = GPIO_MODE_IT_RISING;
  GPIO_InitStruct.Pull = GPIO_NOPULL;
  HAL_GPIO_Init(INTERFACE_INT_GPIO_Port, &GPIO_InitStruct);

  /*Configure GPIO pin : CONTACT_SENSORS_RES0_Pin */
  GPIO_InitStruct.Pin = CONTACT_SENSORS_RES0_Pin;
  GPIO_InitStruct.Mode = GPIO_MODE_INPUT;
  GPIO_InitStruct.Pull = GPIO_NOPULL;
  HAL_GPIO_Init(CONTACT_SENSORS_RES0_GPIO_Port, &GPIO_InitStruct);

}

void Error_Handler(void)
{
  __disable_irq();
  while (1)
  {
  }
}
